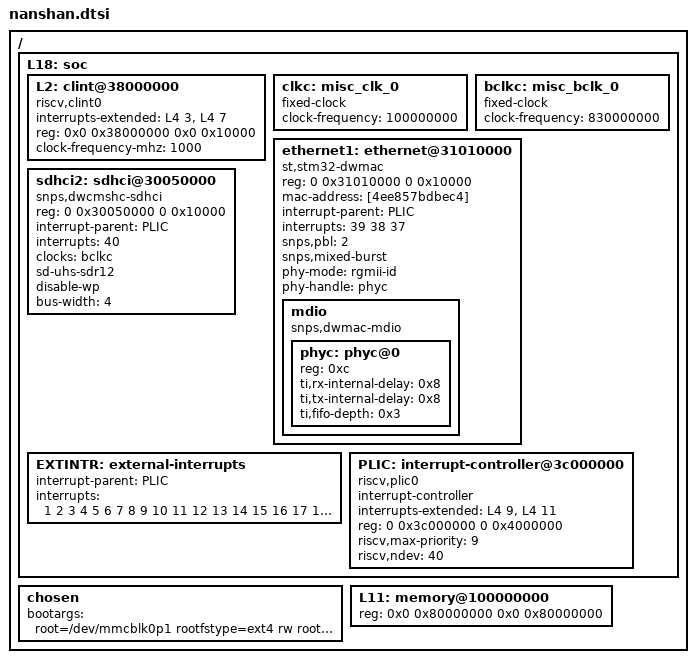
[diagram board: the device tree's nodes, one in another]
/dts-v1/;

/ {
    L18: soc {
        L2: clint@38000000 {
            compatible = "riscv,clint0";
            interrupts-extended = <&L4 3 &L4 7>;
            reg = <0x0 0x38000000 0x0 0x10000>;
            //reg = <0x0 0x2000000 0x0 0x10000>;
            reg-names = "control";
            clock-frequency-mhz = <1000>;
        };
        /*
        L14: serial@60000000 {
            compatible = "xilinx,uartlite";
            //interrupt-parent = <&L1>;
            interrupts = <3>;
            reg = <0x0 0x60000000 0x0 0x1000>;
            reg-names = "control";
        };
        */

        /*
        sdhci: mmc {
            compatible = "nemu-sdhost";
            reg = <0x0 0x40002000 0x0 0x1000>;
        };
        */


        clkc: misc_clk_0 {
            #clock-cells = <0>;
            clock-frequency = <100000000>;
            compatible = "fixed-clock";
        };

        bclkc: misc_bclk_0 {
            #clock-cells = <0>;
            clock-frequency = <830000000>;
            compatible = "fixed-clock";
        };

        ethernet1: ethernet@31010000 {
            compatible = "st,stm32-dwmac", "snps,dwmac-3.50a";
            //compatible = "snps,dwmac-3.50a";
            reg = <0 0x31010000 0 0x10000>;
            reg-names = "stmmaceth";
            mac-address = [4ee857bdbec4];
            interrupt-parent = <&PLIC>;
            interrupts = <39 38 37>;
            interrupt-names = "eth_lpi", "macirq", "eth_wake_irq";
            //clock-names = "stmmaceth";
            //clocks = <&clkc &clkc>;

            //st,syscon = <&syscfg 0x4>;
            snps,pbl = <2>;
            snps,mixed-burst;
            phy-mode = "rgmii-id";
            phy-handle = <&phyc>;
            mdio {
                #address-cells = <1>;
                #size-cells = <0>;
                compatible = "snps,dwmac-mdio";
                phyc: phyc@0 {
                  reg = <0xc>;
                  ti,rx-internal-delay = <0x8>;
                  // txid-insert-below
                  ti,tx-internal-delay = <0x8>;
                  ti,fifo-depth = <0x3>;
                };
            };
            // stmmac driver can not find phy if add this node
            /*
            phyaddr = <0x7>;
            phy-handle = <&phy>;
            mdio {
                #address-cells = <0x1>;
                #size-cells = <0x0>;
                phyaddr = <0x7>;
                compatible = "snps,dwmac-mdio";
                phy: phy@7 {
                    phyaddr = <0x7>;
                    compatible = "marvell,88e1116r";
                    device_type = "ethernet-phy";
                    reg = <0x7>;
                };
            };
            */
        };

        sdhci2: sdhci@30050000 {
            compatible = "snps,dwcmshc-sdhci";
            reg = <0 0x30050000 0 0x10000>;
            interrupt-parent = <&PLIC>;
            interrupts = <40>;
            clocks = <&bclkc>;
            clock-names = "core";
            sd-uhs-sdr12;
            disable-wp;
            bus-width = <4>;
        };

        EXTINTR: external-interrupts {
            interrupt-parent = <&PLIC>;
            interrupts = <1 2 3 4 5 6 7 8 9 10 11 12 13 14 15 16 17 18 19 20 21 22 23 24 25 26 27 28 29 30 31 32 33 34 35 36 37 38 39 40>;
        };
        PLIC: interrupt-controller@3c000000 {
            #interrupt-cells = <1>;
            compatible = "riscv,plic0";
            interrupt-controller;
            interrupts-extended = <&L4 9 &L4 11>;
            //reg = <0 0xc000000 0 0x4000000>;
            reg = <0 0x3c000000 0 0x4000000>;
            reg-names = "control";
            riscv,max-priority = <9>;
            riscv,ndev = <40>;
        };
    };

    chosen {
        bootargs = "root=/dev/mmcblk0p1 rootfstype=ext4 rw rootwait";
    };

    L11: memory@100000000 {
        device_type = "memory";
        reg = <0x0 0x80000000 0x0 0x80000000>;
    };
};
